# CTRL_MMR0_CFG0 register map
Vendor: Texas Instruments
Registers are 32-bit, read-write, reset 0x0 unless marked. A register's access mark holds for its fields unless they carry their own. Offsets are as the file gives them; [hi:lo] are bit positions; {n}, {i} and the like mark numbered series; 'fields as' and 'values as' point back to an identical list.

## CTRL_MMR0_CFG0 (part 2 of 10)
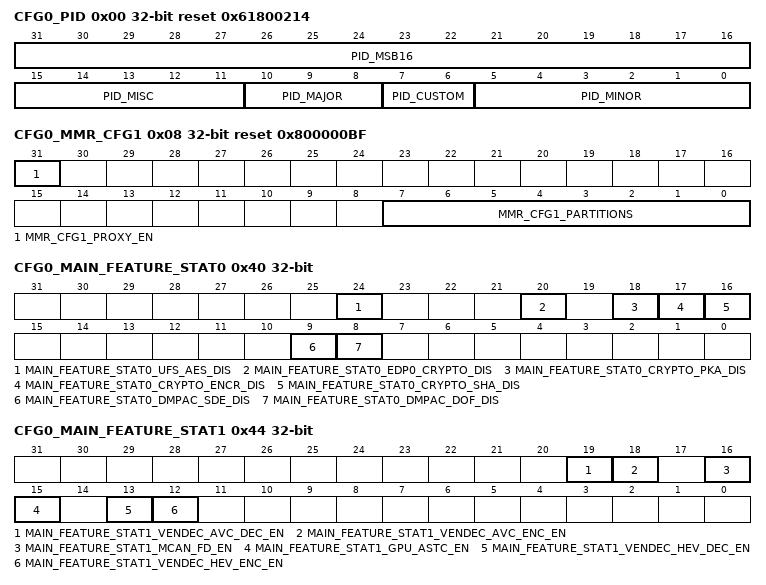
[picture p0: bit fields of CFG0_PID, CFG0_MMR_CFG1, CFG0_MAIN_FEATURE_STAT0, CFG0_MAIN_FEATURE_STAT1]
0x00 CFG0_PID ro reset 0x61800214 — Peripheral release details
  [31:16] PID_MSB16
  [15:11] PID_MISC
  [10:8] PID_MAJOR
  [7:6] PID_CUSTOM — Custom revision number - actual value determined by RTL
  [5:0] PID_MINOR
0x08 CFG0_MMR_CFG1 ro reset 0x800000BF — Indicates the MMR configuration
  [31] MMR_CFG1_PROXY_EN — Proxy addressing enabled
  [7:0] MMR_CFG1_PARTITIONS — Indicates present partitions
0x30 CFG0_MAIN_DEVSTAT — Indicates SoC bootstrap selection. The default value of this register is determined by the SoC bootstrap pins
  [7:0] MAIN_DEVSTAT_BOOTMODE — Specifies the device Primary and Backup boot media.
0x34 CFG0_MAIN_BOOTCFG ro — Indicates SoC bootstrap selection latched at power-on reset. The default value of this register is determined by the SoC bootstrap pins.
  [7:0] MAIN_BOOTCFG_BOOTMODE — Specifies the device Primary and Backup boot media as latched at PORz
0x40 CFG0_MAIN_FEATURE_STAT0 ro — Indicates enable status of MAIN domain IP features
  [24] MAIN_FEATURE_STAT0_UFS_AES_DIS — AES disabled on UFS
  [20] MAIN_FEATURE_STAT0_EDP0_CRYPTO_DIS — HDCP Cryptography disabled on eDP0
  [18] MAIN_FEATURE_STAT0_CRYPTO_PKA_DIS — SA2_UL Crypto Module PKA disabled
  [17] MAIN_FEATURE_STAT0_CRYPTO_ENCR_DIS — SA2_UL Crypto Module AES/3DES/DBRG disabled
  [16] MAIN_FEATURE_STAT0_CRYPTO_SHA_DIS — SA2_UL Crypto Module SHA/MD5 disabled
  [9] MAIN_FEATURE_STAT0_DMPAC_SDE_DIS — DMPAC Stereo Disparity Engine disabled
  [8] MAIN_FEATURE_STAT0_DMPAC_DOF_DIS — DMPAC Dense Optical Flow disabled
0x44 CFG0_MAIN_FEATURE_STAT1 ro — Indicates enable status of MAIN domain IP features
  [19] MAIN_FEATURE_STAT1_VENDEC_AVC_DEC_EN — Video Codec AVC/H.264 decode function enable
  [18] MAIN_FEATURE_STAT1_VENDEC_AVC_ENC_EN — Video Codec AVC/H.264 encode function enable
  [16] MAIN_FEATURE_STAT1_MCAN_FD_EN — FD mode is supported on MAIN MCAN interfaces when set
  [15] MAIN_FEATURE_STAT1_GPU_ASTC_EN — GPU Adaptive Scalable Texture Compression is supported when set
  [13] MAIN_FEATURE_STAT1_VENDEC_HEV_DEC_EN — Video Codec HEVC/H.265 decode function enable
  [12] MAIN_FEATURE_STAT1_VENDEC_HEV_ENC_EN — Video Codec HEVC/H.265 encode function enable
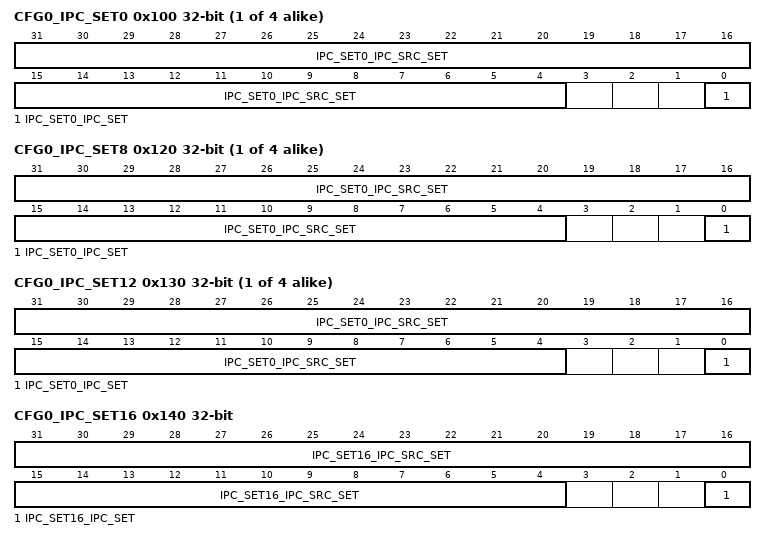
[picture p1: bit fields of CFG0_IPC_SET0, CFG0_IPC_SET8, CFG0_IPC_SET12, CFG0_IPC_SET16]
{0x100+4i} CFG0_IPC_SET{i} access not given (i=0..3) — Generate interprocessor communication interrupt to C71x core{i}
  [31:4] IPC_SET{i}_IPC_SRC_SET — Read returns current valueWrite: 0 - No effect 1 - Sets both SRC_SETx and the SRC_CLRx bit in the corresponding IPC_CLR register (access R/W1TS)
  [0] IPC_SET{i}_IPC_SET — Read returns 0Write: 0 - No effect 1 - Sets both the IPC_SET and the IPC_CLR bit in the corresponding IPC_CLR register (access R/W1TS)
{0x100+4i} CFG0_IPC_SET{i} access not given (i=8..11) — Generate interprocessor communication interrupt to ARM MPU cluster0 core{i-8}
  fields as CFG0_IPC_SET0
{0x100+4i} CFG0_IPC_SET{i} access not given (i=12..15) — Generate interprocessor communication interrupt to ARM MPU cluster1 core{i-12}
  fields as CFG0_IPC_SET0
0x140 CFG0_IPC_SET16 access not given — Generate interprocessor communication interrupt to MAIN R5 cluster0 core0
  [31:4] IPC_SET16_IPC_SRC_SET — Read returns current valueWrite: 0 - No effect 1 - Sets both SRC_SETx and the SRC_CLRx bit in the corresponding IPC_CLR register (access R/W1TS)
  [0] IPC_SET16_IPC_SET — Read returns 0Write: 0 - No effect 1 - Sets both the IPC_SET and the IPC_CLR bit in the corresponding IPC_CLR register (access R/W1TS)
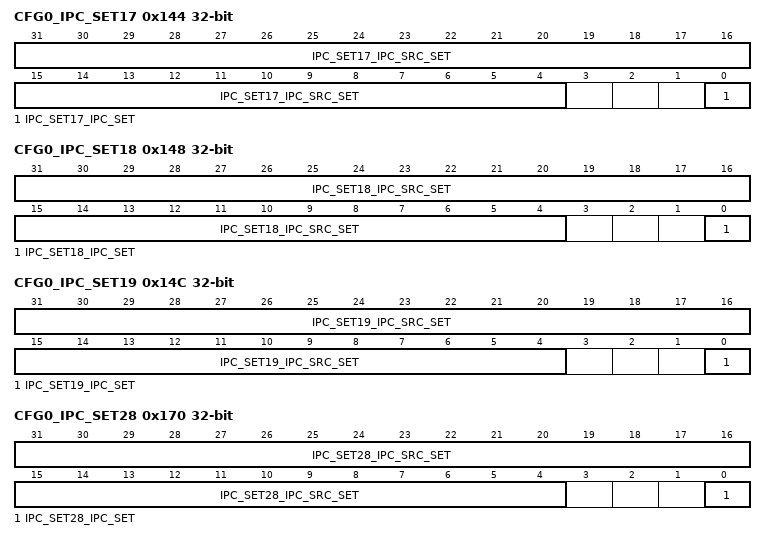
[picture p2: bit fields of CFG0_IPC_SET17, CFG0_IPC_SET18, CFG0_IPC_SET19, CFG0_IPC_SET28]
0x144 CFG0_IPC_SET17 access not given — Generate interprocessor communication interrupt to MAIN R5 cluster0 core1
  [31:4] IPC_SET17_IPC_SRC_SET — Read returns current valueWrite: 0 - No effect 1 - Sets both SRC_SETx and the SRC_CLRx bit in the corresponding IPC_CLR register (access R/W1TS)
  [0] IPC_SET17_IPC_SET — Read returns 0Write: 0 - No effect 1 - Sets both the IPC_SET and the IPC_CLR bit in the corresponding IPC_CLR register (access R/W1TS)
0x148 CFG0_IPC_SET18 access not given — Generate interprocessor communication interrupt to MAIN R5 cluster1 core0
  [31:4] IPC_SET18_IPC_SRC_SET — Read returns current valueWrite: 0 - No effect 1 - Sets both SRC_SETx and the SRC_CLRx bit in the corresponding IPC_CLR register (access R/W1TS)
  [0] IPC_SET18_IPC_SET — Read returns 0Write: 0 - No effect 1 - Sets both the IPC_SET and the IPC_CLR bit in the corresponding IPC_CLR register (access R/W1TS)
0x14C CFG0_IPC_SET19 access not given — Generate interprocessor communication interrupt to MAIN R5 cluster1 core1
  [31:4] IPC_SET19_IPC_SRC_SET — Read returns current valueWrite: 0 - No effect 1 - Sets both SRC_SETx and the SRC_CLRx bit in the corresponding IPC_CLR register (access R/W1TS)
  [0] IPC_SET19_IPC_SET — Read returns 0Write: 0 - No effect 1 - Sets both the IPC_SET and the IPC_CLR bit in the corresponding IPC_CLR register (access R/W1TS)
0x170 CFG0_IPC_SET28 access not given — Generate interprocessor communication interrupt to MAIN R5 cluster2 core0
  [31:4] IPC_SET28_IPC_SRC_SET — Read returns current valueWrite: 0 - No effect 1 - Sets both SRC_SETx and the SRC_CLRx bit in the corresponding IPC_CLR register (access R/W1TS)
  [0] IPC_SET28_IPC_SET — Read returns 0Write: 0 - No effect 1 - Sets both the IPC_SET and the IPC_CLR bit in the corresponding IPC_CLR register (access R/W1TS)
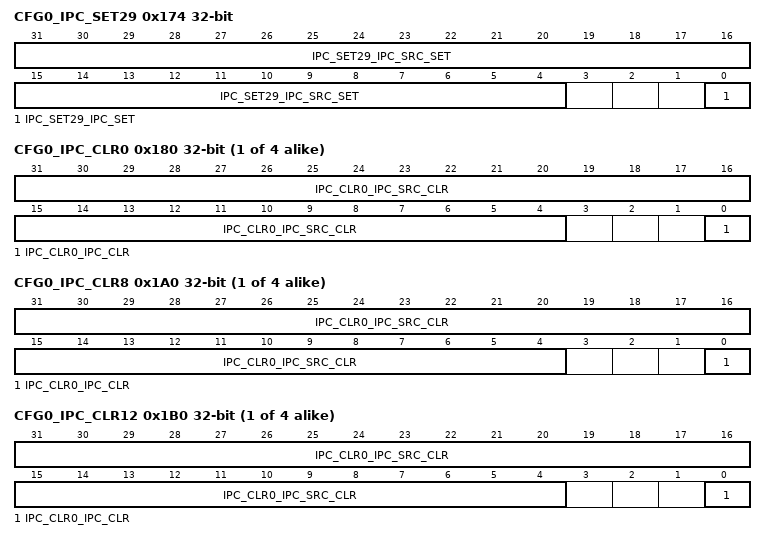
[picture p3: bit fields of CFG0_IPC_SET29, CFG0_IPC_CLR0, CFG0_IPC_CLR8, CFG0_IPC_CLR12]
0x174 CFG0_IPC_SET29 access not given — Generate interprocessor communication interrupt to MAIN R5 cluster2 core1
  [31:4] IPC_SET29_IPC_SRC_SET — Read returns current valueWrite: 0 - No effect 1 - Sets both SRC_SETx and the SRC_CLRx bit in the corresponding IPC_CLR register (access R/W1TS)
  [0] IPC_SET29_IPC_SET — Read returns 0Write: 0 - No effect 1 - Sets both the IPC_SET and the IPC_CLR bit in the corresponding IPC_CLR register (access R/W1TS)
{0x180+4i} CFG0_IPC_CLR{i} access not given (i=0..3) — Acknowledge interprocessor communication interrupt to C71x core{i}
  [31:4] IPC_CLR{i}_IPC_SRC_CLR — Read returns current valueWrite: 0 - No effect 1 - Clears both SRC_CLRx and the SRC_SETx bit in the corresponding IPC_GEN register (access R/W1TC)
  [0] IPC_CLR{i}_IPC_CLR — Read returns current valueWrite: 0 - No effect 1 - Clears both IPC_CLR and the IPC_SET bit in the corresponding IPC_SET register (access R/W1TC)
{0x180+4i} CFG0_IPC_CLR{i} access not given (i=8..11) — Acknowledge interprocessor communication interrupt to ARM MPU cluster0 core{i-8}
  fields as CFG0_IPC_CLR0
{0x180+4i} CFG0_IPC_CLR{i} access not given (i=12..15) — Acknowledge interprocessor communication interrupt to ARM MPU cluster1 core{i-12}
  fields as CFG0_IPC_CLR0
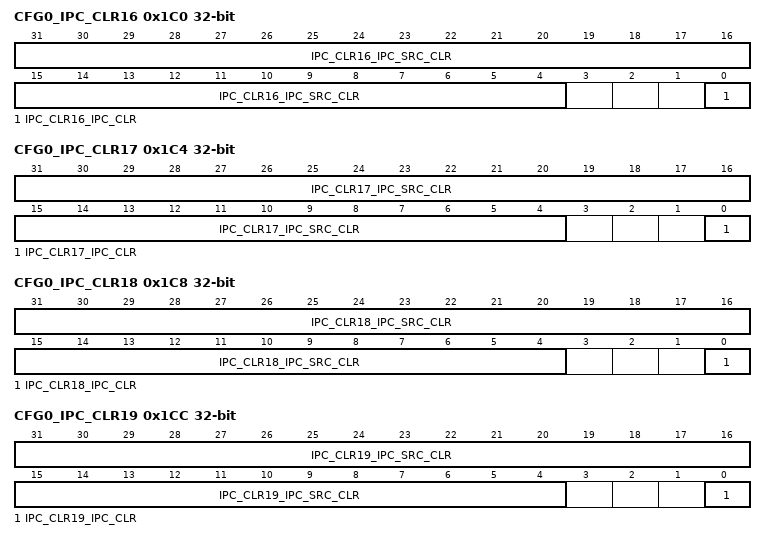
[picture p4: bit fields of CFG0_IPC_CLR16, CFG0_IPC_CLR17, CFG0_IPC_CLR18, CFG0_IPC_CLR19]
0x1C0 CFG0_IPC_CLR16 access not given — Acknowledge interprocessor communication interrupt to MAIN R5 cluster0 core0
  [31:4] IPC_CLR16_IPC_SRC_CLR — Read returns current valueWrite: 0 - No effect 1 - Clears both SRC_CLRx and the SRC_SETx bit in the corresponding IPC_GEN register (access R/W1TC)
  [0] IPC_CLR16_IPC_CLR — Read returns current valueWrite: 0 - No effect 1 - Clears both IPC_CLR and the IPC_SET bit in the corresponding IPC_SET register (access R/W1TC)
0x1C4 CFG0_IPC_CLR17 access not given — Acknowledge interprocessor communication interrupt to MAIN R5 cluster0 core1
  [31:4] IPC_CLR17_IPC_SRC_CLR — Read returns current valueWrite: 0 - No effect 1 - Clears both SRC_CLRx and the SRC_SETx bit in the corresponding IPC_GEN register (access R/W1TC)
  [0] IPC_CLR17_IPC_CLR — Read returns current valueWrite: 0 - No effect 1 - Clears both IPC_CLR and the IPC_SET bit in the corresponding IPC_SET register (access R/W1TC)
0x1C8 CFG0_IPC_CLR18 access not given — Acknowledge interprocessor communication interrupt to MAIN R5 cluster1 core0
  [31:4] IPC_CLR18_IPC_SRC_CLR — Read returns current valueWrite: 0 - No effect 1 - Clears both SRC_CLRx and the SRC_SETx bit in the corresponding IPC_GEN register (access R/W1TC)
  [0] IPC_CLR18_IPC_CLR — Read returns current valueWrite: 0 - No effect 1 - Clears both IPC_CLR and the IPC_SET bit in the corresponding IPC_SET register (access R/W1TC)
0x1CC CFG0_IPC_CLR19 access not given — Acknowledge interprocessor communication interrupt to MAIN R5 cluster1 core1
  [31:4] IPC_CLR19_IPC_SRC_CLR — Read returns current valueWrite: 0 - No effect 1 - Clears both SRC_CLRx and the SRC_SETx bit in the corresponding IPC_GEN register (access R/W1TC)
  [0] IPC_CLR19_IPC_CLR — Read returns current valueWrite: 0 - No effect 1 - Clears both IPC_CLR and the IPC_SET bit in the corresponding IPC_SET register (access R/W1TC)
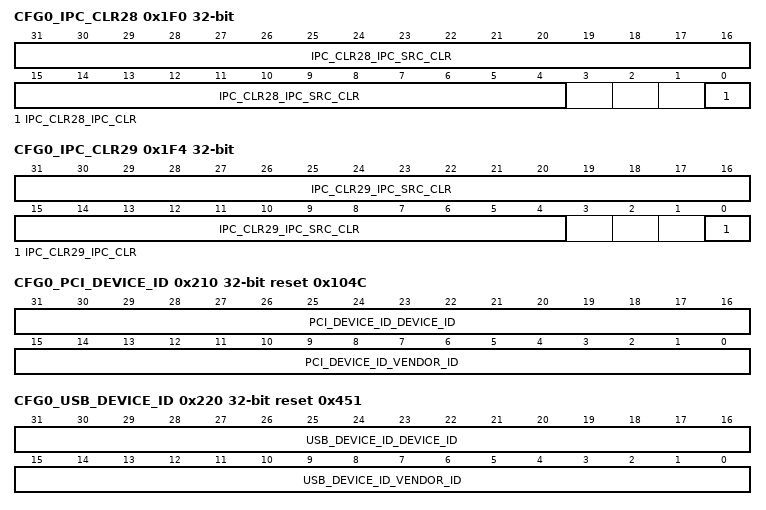
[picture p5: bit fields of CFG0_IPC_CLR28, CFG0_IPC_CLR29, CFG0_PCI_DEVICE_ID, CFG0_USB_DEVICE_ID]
0x1F0 CFG0_IPC_CLR28 access not given — Acknowledge interprocessor communication interrupt to MAIN R5 cluster2 core0
  [31:4] IPC_CLR28_IPC_SRC_CLR — Read returns current valueWrite: 0 - No effect 1 - Clears both SRC_CLRx and the SRC_SETx bit in the corresponding IPC_GEN register (access R/W1TC)
  [0] IPC_CLR28_IPC_CLR — Read returns current valueWrite: 0 - No effect 1 - Clears both IPC_CLR and the IPC_SET bit in the corresponding IPC_SET register (access R/W1TC)
0x1F4 CFG0_IPC_CLR29 access not given — Acknowledge interprocessor communication interrupt to MAIN R5 cluster2 core1
  [31:4] IPC_CLR29_IPC_SRC_CLR — Read returns current valueWrite: 0 - No effect 1 - Clears both SRC_CLRx and the SRC_SETx bit in the corresponding IPC_GEN register (access R/W1TC)
  [0] IPC_CLR29_IPC_CLR — Read returns current valueWrite: 0 - No effect 1 - Clears both IPC_CLR and the IPC_SET bit in the corresponding IPC_SET register (access R/W1TC)
0x210 CFG0_PCI_DEVICE_ID reset 0x104C — PCIe device ID and vendor ID register
  [31:16] PCI_DEVICE_ID_DEVICE_ID — Product ID defaults to 16'hB012
  [15:0] PCI_DEVICE_ID_VENDOR_ID — TI Vendor ID
0x220 CFG0_USB_DEVICE_ID reset 0x451 — USB device and vendor ID register
  [31:16] USB_DEVICE_ID_DEVICE_ID — Product ID defaults to 16'h6167
  [15:0] USB_DEVICE_ID_VENDOR_ID — TI Vendor ID
{0x1008+0x4000*i} CFG0_LOCK{i}_KICK0 (i=0..3) — This register must be written with the designated key value followed by a write to LOCK{i}_KICK1 with its key value before write-protected Partition {i} registers can be written.
  [31:0] LOCK{i}_KICK0 — - KICK0 component
{0x100C+0x4000*i} CFG0_LOCK{i}_KICK1 (i=0..3) — This register must be written with the designated key value after a write to LOCK{i}_KICK0 with its key value before write-protected Partition {i} registers can be written.
  [31:0] LOCK{i}_KICK1 — - KICK1 component
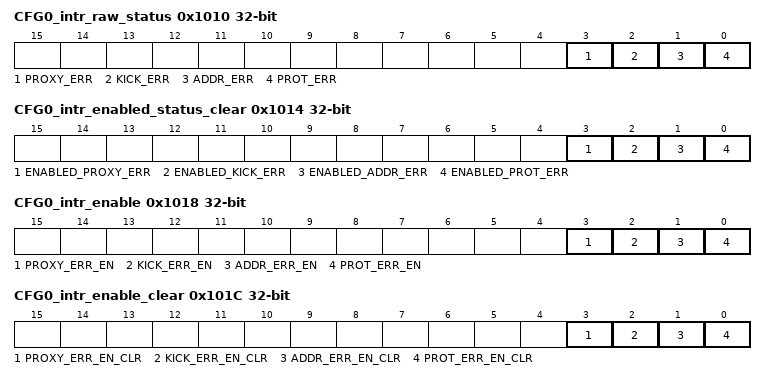
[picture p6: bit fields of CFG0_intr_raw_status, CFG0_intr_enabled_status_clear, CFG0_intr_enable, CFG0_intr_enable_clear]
0x1010 CFG0_intr_raw_status access not given
  [3] PROXY_ERR — Proxy0 access violation error. Raw status is read. Write a 1 to set the status. Writing a 0 has no effect. (access R/W1TS)
  [2] KICK_ERR — Kick access violation error. Raw status is read. Write a 1 to set the status. Writing a 0 has no effect. (access R/W1TS)
  [1] ADDR_ERR — Addressing violation error. Raw status is read. Write a 1 to set the status. Writing a 0 has no effect. (access R/W1TS)
  [0] PROT_ERR — Protection violation error. Raw status is read. Write a 1 to set the status. Writing a 0 has no effect. (access R/W1TS)
0x1014 CFG0_intr_enabled_status_clear access not given
  [3] ENABLED_PROXY_ERR — Proxy0 access violation error. Enabled status is read. Write a 1 to clear the status. Writing a 0 has no effect. (access R/W1TC)
  [2] ENABLED_KICK_ERR — Kick access violation error. Enabled status is read. Write a 1 to clear the status. Writing a 0 has no effect. (access R/W1TC)
  [1] ENABLED_ADDR_ERR — Addressing violation error. Enabled status is read. Write a 1 to clear the status. Writing a 0 has no effect. (access R/W1TC)
  [0] ENABLED_PROT_ERR — Protection violation error. Enabled status is read. Write a 1 to clear the status. Writing a 0 has no effect. (access R/W1TC)
0x1018 CFG0_intr_enable access not given
  [3] PROXY_ERR_EN — Proxy0 access violation error enable. Write a 1 to set the enable. Writing a 0 has no effect. (access R/W1TS)
  [2] KICK_ERR_EN — Kick access violation error enable. Write a 1 to set the enable. Writing a 0 has no effect. (access R/W1TS)
  [1] ADDR_ERR_EN — Addressing violation error enable. Write a 1 to set the enable. Writing a 0 has no effect. (access R/W1TS)
  [0] PROT_ERR_EN — Protection violation error enable. Write a 1 to set the enable. Writing a 0 has no effect. (access R/W1TS)
0x101C CFG0_intr_enable_clear access not given
  [3] PROXY_ERR_EN_CLR — Proxy0 access violation error enable clear. Write a 1 to clear the enable. Writing a 0 has no effect. (access R/W1TC)
  [2] KICK_ERR_EN_CLR — Kick access violation error enable clear. Write a 1 to clear the enable. Writing a 0 has no effect. (access R/W1TC)
  [1] ADDR_ERR_EN_CLR — Addressing violation error enable clear. Write a 1 to clear the enable. Writing a 0 has no effect. (access R/W1TC)
  [0] PROT_ERR_EN_CLR — Protection violation error enable clear. Write a 1 to clear the enable. Writing a 0 has no effect. (access R/W1TC)
0x1020 CFG0_eoi — This register should be written with interrupt distribution value required by the device architecture to indicate service completion of the MMR interrupt. This value is not used on this device.
  [7:0] EOI_VECTOR — EOI vector value. Write this with interrupt distribution value in the chip.
0x1024 CFG0_fault_address ro
  [31:0] FAULT_ADDR — Fault Address.
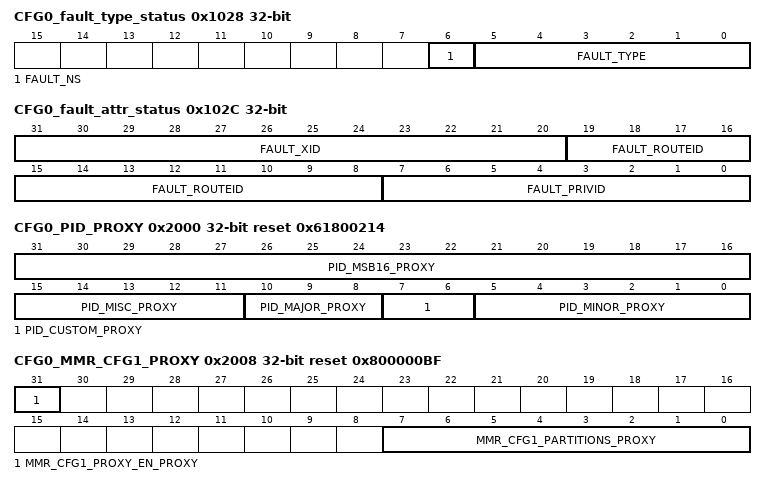
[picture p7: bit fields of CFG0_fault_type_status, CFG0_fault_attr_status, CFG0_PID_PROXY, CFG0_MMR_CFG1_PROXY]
0x1028 CFG0_fault_type_status ro
  [6] FAULT_NS — Non-secure access.
  [5:0] FAULT_TYPE — Fault Type 10_0000 = Supervisor read fault - priv = 1 dir = 1 dtype != 1 01_0000 = Supervisor write fault - priv = 1 dir = 0 00_1000 = Supervisor execute fault - priv = 1 dir = 1 dtype = 1 00_0100 = User read fault - priv = 0 dir = 1 dtype = 1 00_0010 = User write fault - priv = 0 dir = 0 00_0001 = User execute fault - priv = 0 dir = 1 dtype = 1 00_0000 = No fault
0x102C CFG0_fault_attr_status ro
  [31:20] FAULT_XID — XID.
  [19:8] FAULT_ROUTEID — Route ID.
  [7:0] FAULT_PRIVID — Privilege ID.
0x1030 CFG0_fault_clear wo
  [0] FAULT_CLR — Fault clear. Writing a 1 clears the current fault. Writing a 0 has no effect.
{0x1100+4i} CFG0_CLAIMREG_P0_R{i}_READONLY ro (i=0..6)
  [31:0] CLAIMREG_P0_R{i}_READONLY — Claim bits for Partition 0
0x2000 CFG0_PID_PROXY ro reset 0x61800214 — Peripheral release details
  [31:16] PID_MSB16_PROXY
  [15:11] PID_MISC_PROXY
  [10:8] PID_MAJOR_PROXY
  [7:6] PID_CUSTOM_PROXY — Custom revision number - actual value determined by RTL
  [5:0] PID_MINOR_PROXY
0x2008 CFG0_MMR_CFG1_PROXY ro reset 0x800000BF — Indicates the MMR configuration
  [31] MMR_CFG1_PROXY_EN_PROXY — Proxy addressing enabled
  [7:0] MMR_CFG1_PARTITIONS_PROXY — Indicates present partitions
0x2030 CFG0_MAIN_DEVSTAT_PROXY — Indicates SoC bootstrap selection. The default value of this register is determined by the SoC bootstrap pins
  [7:0] MAIN_DEVSTAT_BOOTMODE_PROXY — Specifies the device Primary and Backup boot media.
0x2034 CFG0_MAIN_BOOTCFG_PROXY ro — Indicates SoC bootstrap selection latched at power-on reset. The default value of this register is determined by the SoC bootstrap pins.
  [7:0] MAIN_BOOTCFG_BOOTMODE_PROXY — Specifies the device Primary and Backup boot media as latched at PORz
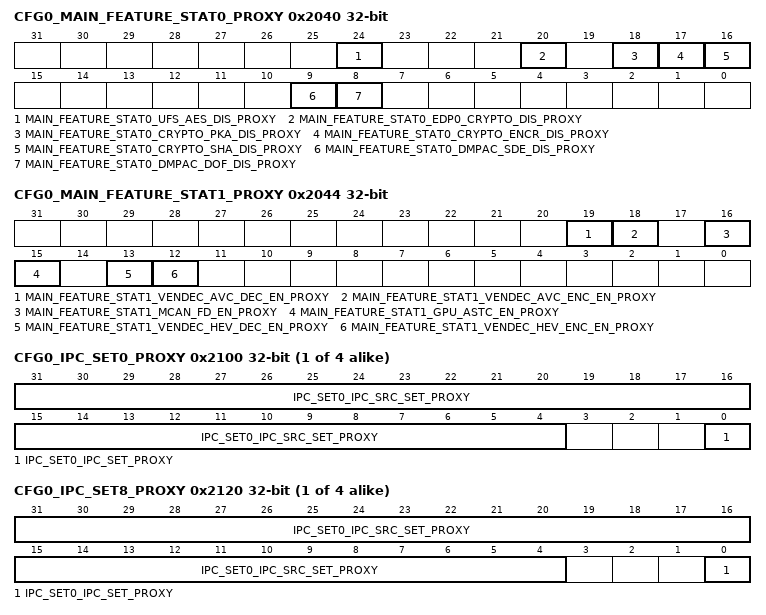
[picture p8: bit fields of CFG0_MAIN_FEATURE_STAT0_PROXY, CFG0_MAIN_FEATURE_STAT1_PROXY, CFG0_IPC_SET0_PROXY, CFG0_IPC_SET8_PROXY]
0x2040 CFG0_MAIN_FEATURE_STAT0_PROXY ro — Indicates enable status of MAIN domain IP features
  [24] MAIN_FEATURE_STAT0_UFS_AES_DIS_PROXY — AES disabled on UFS
  [20] MAIN_FEATURE_STAT0_EDP0_CRYPTO_DIS_PROXY — HDCP Cryptography disabled on eDP0
  [18] MAIN_FEATURE_STAT0_CRYPTO_PKA_DIS_PROXY — SA2_UL Crypto Module PKA disabled
  [17] MAIN_FEATURE_STAT0_CRYPTO_ENCR_DIS_PROXY — SA2_UL Crypto Module AES/3DES/DBRG disabled
  [16] MAIN_FEATURE_STAT0_CRYPTO_SHA_DIS_PROXY — SA2_UL Crypto Module SHA/MD5 disabled
  [9] MAIN_FEATURE_STAT0_DMPAC_SDE_DIS_PROXY — DMPAC Stereo Disparity Engine disabled
  [8] MAIN_FEATURE_STAT0_DMPAC_DOF_DIS_PROXY — DMPAC Dense Optical Flow disabled
0x2044 CFG0_MAIN_FEATURE_STAT1_PROXY ro — Indicates enable status of MAIN domain IP features
  [19] MAIN_FEATURE_STAT1_VENDEC_AVC_DEC_EN_PROXY — Video Codec AVC/H.264 decode function enable
  [18] MAIN_FEATURE_STAT1_VENDEC_AVC_ENC_EN_PROXY — Video Codec AVC/H.264 encode function enable
  [16] MAIN_FEATURE_STAT1_MCAN_FD_EN_PROXY — FD mode is supported on MAIN MCAN interfaces when set
  [15] MAIN_FEATURE_STAT1_GPU_ASTC_EN_PROXY — GPU Adaptive Scalable Texture Compression is supported when set
  [13] MAIN_FEATURE_STAT1_VENDEC_HEV_DEC_EN_PROXY — Video Codec HEVC/H.265 decode function enable
  [12] MAIN_FEATURE_STAT1_VENDEC_HEV_ENC_EN_PROXY — Video Codec HEVC/H.265 encode function enable
{0x2100+4i} CFG0_IPC_SET{i}_PROXY access not given (i=0..3) — Generate interprocessor communication interrupt to C71x core{i}
  [31:4] IPC_SET{i}_IPC_SRC_SET_PROXY — Read returns current valueWrite: 0 - No effect 1 - Sets both SRC_SETx and the SRC_CLRx bit in the corresponding IPC_CLR register (access R/W1TS)
  [0] IPC_SET{i}_IPC_SET_PROXY — Read returns 0Write: 0 - No effect 1 - Sets both the IPC_SET and the IPC_CLR bit in the corresponding IPC_CLR register (access R/W1TS)
{0x2100+4i} CFG0_IPC_SET{i}_PROXY access not given (i=8..11) — Generate interprocessor communication interrupt to ARM MPU cluster0 core{i-8}
  fields as CFG0_IPC_SET0_PROXY
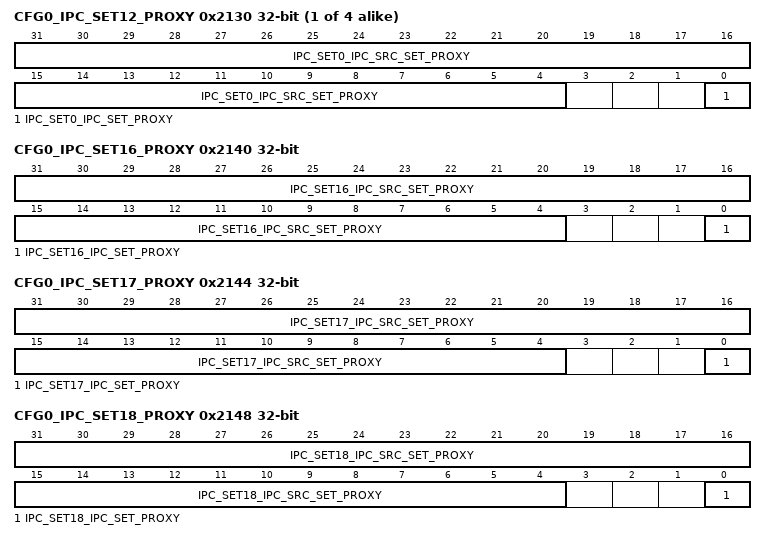
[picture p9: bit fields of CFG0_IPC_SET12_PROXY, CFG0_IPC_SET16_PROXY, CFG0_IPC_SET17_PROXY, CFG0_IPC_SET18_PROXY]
{0x2100+4i} CFG0_IPC_SET{i}_PROXY access not given (i=12..15) — Generate interprocessor communication interrupt to ARM MPU cluster1 core{i-12}
  fields as CFG0_IPC_SET0_PROXY
0x2140 CFG0_IPC_SET16_PROXY access not given — Generate interprocessor communication interrupt to MAIN R5 cluster0 core0
  [31:4] IPC_SET16_IPC_SRC_SET_PROXY — Read returns current valueWrite: 0 - No effect 1 - Sets both SRC_SETx and the SRC_CLRx bit in the corresponding IPC_CLR register (access R/W1TS)
  [0] IPC_SET16_IPC_SET_PROXY — Read returns 0Write: 0 - No effect 1 - Sets both the IPC_SET and the IPC_CLR bit in the corresponding IPC_CLR register (access R/W1TS)
0x2144 CFG0_IPC_SET17_PROXY access not given — Generate interprocessor communication interrupt to MAIN R5 cluster0 core1
  [31:4] IPC_SET17_IPC_SRC_SET_PROXY — Read returns current valueWrite: 0 - No effect 1 - Sets both SRC_SETx and the SRC_CLRx bit in the corresponding IPC_CLR register (access R/W1TS)
  [0] IPC_SET17_IPC_SET_PROXY — Read returns 0Write: 0 - No effect 1 - Sets both the IPC_SET and the IPC_CLR bit in the corresponding IPC_CLR register (access R/W1TS)
0x2148 CFG0_IPC_SET18_PROXY access not given — Generate interprocessor communication interrupt to MAIN R5 cluster1 core0
  [31:4] IPC_SET18_IPC_SRC_SET_PROXY — Read returns current valueWrite: 0 - No effect 1 - Sets both SRC_SETx and the SRC_CLRx bit in the corresponding IPC_CLR register (access R/W1TS)
  [0] IPC_SET18_IPC_SET_PROXY — Read returns 0Write: 0 - No effect 1 - Sets both the IPC_SET and the IPC_CLR bit in the corresponding IPC_CLR register (access R/W1TS)
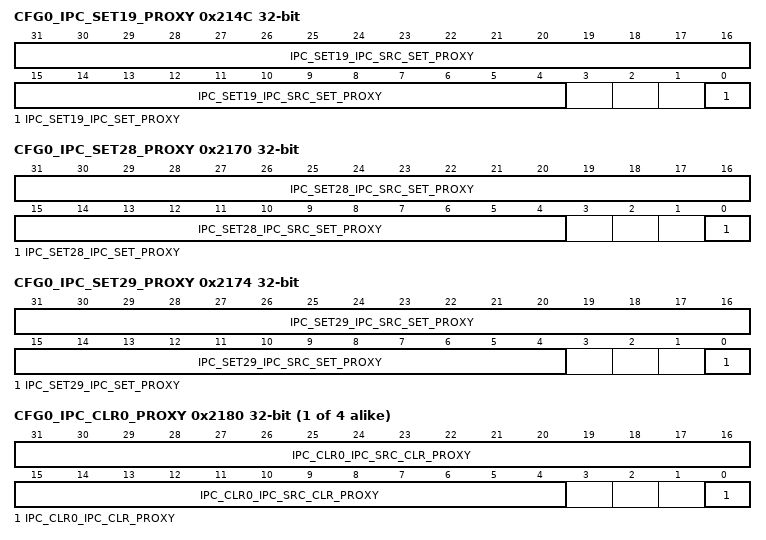
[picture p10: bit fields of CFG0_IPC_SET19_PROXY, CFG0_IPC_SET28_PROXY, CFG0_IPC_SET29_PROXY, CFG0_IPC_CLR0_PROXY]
0x214C CFG0_IPC_SET19_PROXY access not given — Generate interprocessor communication interrupt to MAIN R5 cluster1 core1
  [31:4] IPC_SET19_IPC_SRC_SET_PROXY — Read returns current valueWrite: 0 - No effect 1 - Sets both SRC_SETx and the SRC_CLRx bit in the corresponding IPC_CLR register (access R/W1TS)
  [0] IPC_SET19_IPC_SET_PROXY — Read returns 0Write: 0 - No effect 1 - Sets both the IPC_SET and the IPC_CLR bit in the corresponding IPC_CLR register (access R/W1TS)
0x2170 CFG0_IPC_SET28_PROXY access not given — Generate interprocessor communication interrupt to MAIN R5 cluster2 core0
  [31:4] IPC_SET28_IPC_SRC_SET_PROXY — Read returns current valueWrite: 0 - No effect 1 - Sets both SRC_SETx and the SRC_CLRx bit in the corresponding IPC_CLR register (access R/W1TS)
  [0] IPC_SET28_IPC_SET_PROXY — Read returns 0Write: 0 - No effect 1 - Sets both the IPC_SET and the IPC_CLR bit in the corresponding IPC_CLR register (access R/W1TS)
0x2174 CFG0_IPC_SET29_PROXY access not given — Generate interprocessor communication interrupt to MAIN R5 cluster2 core1
  [31:4] IPC_SET29_IPC_SRC_SET_PROXY — Read returns current valueWrite: 0 - No effect 1 - Sets both SRC_SETx and the SRC_CLRx bit in the corresponding IPC_CLR register (access R/W1TS)
  [0] IPC_SET29_IPC_SET_PROXY — Read returns 0Write: 0 - No effect 1 - Sets both the IPC_SET and the IPC_CLR bit in the corresponding IPC_CLR register (access R/W1TS)
{0x2180+4i} CFG0_IPC_CLR{i}_PROXY access not given (i=0..3) — Acknowledge interprocessor communication interrupt to C71x core{i}
  [31:4] IPC_CLR{i}_IPC_SRC_CLR_PROXY — Read returns current valueWrite: 0 - No effect 1 - Clears both SRC_CLRx and the SRC_SETx bit in the corresponding IPC_GEN register (access R/W1TC)
  [0] IPC_CLR{i}_IPC_CLR_PROXY — Read returns current valueWrite: 0 - No effect 1 - Clears both IPC_CLR and the IPC_SET bit in the corresponding IPC_SET register (access R/W1TC)
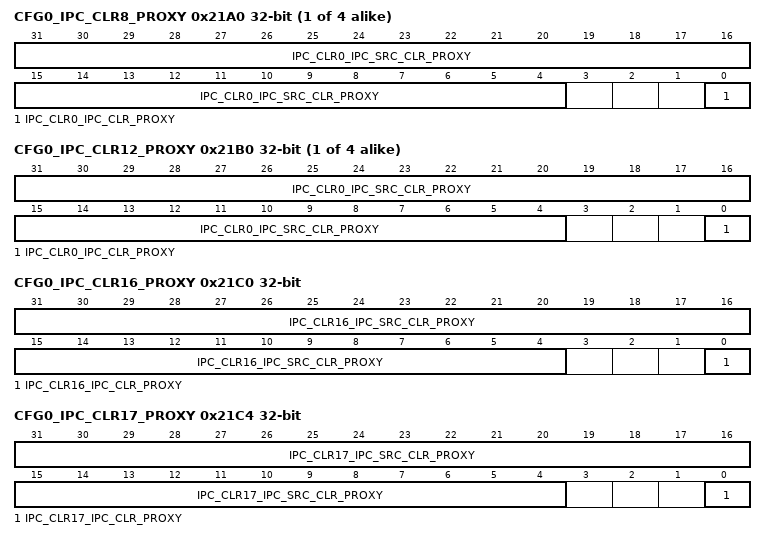
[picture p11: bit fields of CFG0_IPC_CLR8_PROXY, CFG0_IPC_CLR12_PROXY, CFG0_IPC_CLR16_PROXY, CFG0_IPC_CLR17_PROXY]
{0x2180+4i} CFG0_IPC_CLR{i}_PROXY access not given (i=8..11) — Acknowledge interprocessor communication interrupt to ARM MPU cluster0 core{i-8}
  fields as CFG0_IPC_CLR0_PROXY
{0x2180+4i} CFG0_IPC_CLR{i}_PROXY access not given (i=12..15) — Acknowledge interprocessor communication interrupt to ARM MPU cluster1 core{i-12}
  fields as CFG0_IPC_CLR0_PROXY
0x21C0 CFG0_IPC_CLR16_PROXY access not given — Acknowledge interprocessor communication interrupt to MAIN R5 cluster0 core0
  [31:4] IPC_CLR16_IPC_SRC_CLR_PROXY — Read returns current valueWrite: 0 - No effect 1 - Clears both SRC_CLRx and the SRC_SETx bit in the corresponding IPC_GEN register (access R/W1TC)
  [0] IPC_CLR16_IPC_CLR_PROXY — Read returns current valueWrite: 0 - No effect 1 - Clears both IPC_CLR and the IPC_SET bit in the corresponding IPC_SET register (access R/W1TC)
0x21C4 CFG0_IPC_CLR17_PROXY access not given — Acknowledge interprocessor communication interrupt to MAIN R5 cluster0 core1
  [31:4] IPC_CLR17_IPC_SRC_CLR_PROXY — Read returns current valueWrite: 0 - No effect 1 - Clears both SRC_CLRx and the SRC_SETx bit in the corresponding IPC_GEN register (access R/W1TC)
  [0] IPC_CLR17_IPC_CLR_PROXY — Read returns current valueWrite: 0 - No effect 1 - Clears both IPC_CLR and the IPC_SET bit in the corresponding IPC_SET register (access R/W1TC)
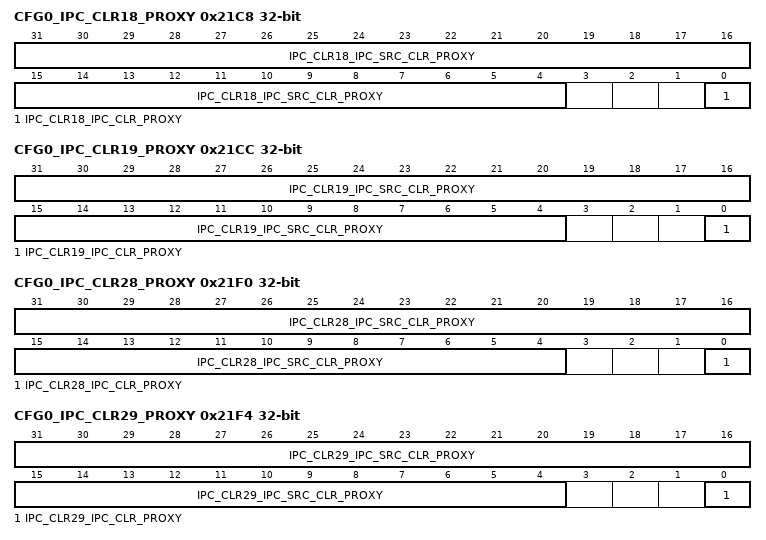
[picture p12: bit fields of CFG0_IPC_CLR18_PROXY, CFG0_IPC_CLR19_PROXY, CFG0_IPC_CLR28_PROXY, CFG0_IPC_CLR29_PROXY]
0x21C8 CFG0_IPC_CLR18_PROXY access not given — Acknowledge interprocessor communication interrupt to MAIN R5 cluster1 core0
  [31:4] IPC_CLR18_IPC_SRC_CLR_PROXY — Read returns current valueWrite: 0 - No effect 1 - Clears both SRC_CLRx and the SRC_SETx bit in the corresponding IPC_GEN register (access R/W1TC)
  [0] IPC_CLR18_IPC_CLR_PROXY — Read returns current valueWrite: 0 - No effect 1 - Clears both IPC_CLR and the IPC_SET bit in the corresponding IPC_SET register (access R/W1TC)
0x21CC CFG0_IPC_CLR19_PROXY access not given — Acknowledge interprocessor communication interrupt to MAIN R5 cluster1 core1
  [31:4] IPC_CLR19_IPC_SRC_CLR_PROXY — Read returns current valueWrite: 0 - No effect 1 - Clears both SRC_CLRx and the SRC_SETx bit in the corresponding IPC_GEN register (access R/W1TC)
  [0] IPC_CLR19_IPC_CLR_PROXY — Read returns current valueWrite: 0 - No effect 1 - Clears both IPC_CLR and the IPC_SET bit in the corresponding IPC_SET register (access R/W1TC)
0x21F0 CFG0_IPC_CLR28_PROXY access not given — Acknowledge interprocessor communication interrupt to MAIN R5 cluster2 core0
  [31:4] IPC_CLR28_IPC_SRC_CLR_PROXY — Read returns current valueWrite: 0 - No effect 1 - Clears both SRC_CLRx and the SRC_SETx bit in the corresponding IPC_GEN register (access R/W1TC)
  [0] IPC_CLR28_IPC_CLR_PROXY — Read returns current valueWrite: 0 - No effect 1 - Clears both IPC_CLR and the IPC_SET bit in the corresponding IPC_SET register (access R/W1TC)
0x21F4 CFG0_IPC_CLR29_PROXY access not given — Acknowledge interprocessor communication interrupt to MAIN R5 cluster2 core1
  [31:4] IPC_CLR29_IPC_SRC_CLR_PROXY — Read returns current valueWrite: 0 - No effect 1 - Clears both SRC_CLRx and the SRC_SETx bit in the corresponding IPC_GEN register (access R/W1TC)
  [0] IPC_CLR29_IPC_CLR_PROXY — Read returns current valueWrite: 0 - No effect 1 - Clears both IPC_CLR and the IPC_SET bit in the corresponding IPC_SET register (access R/W1TC)
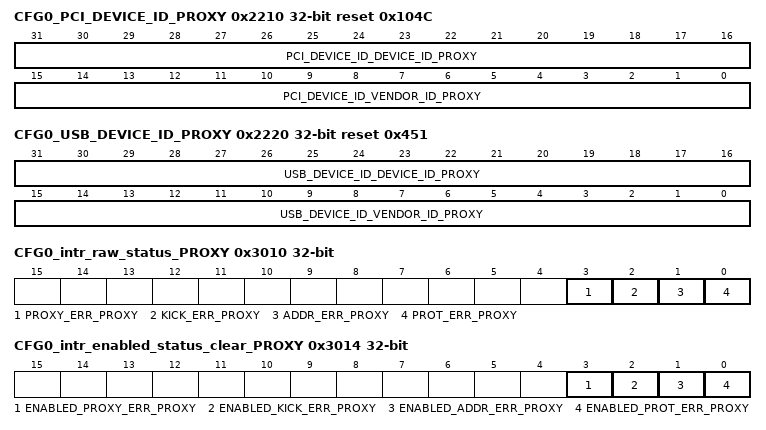
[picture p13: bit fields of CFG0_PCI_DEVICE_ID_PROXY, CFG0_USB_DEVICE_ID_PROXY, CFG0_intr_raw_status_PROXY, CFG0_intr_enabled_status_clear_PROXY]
0x2210 CFG0_PCI_DEVICE_ID_PROXY reset 0x104C — PCIe device ID and vendor ID register
  [31:16] PCI_DEVICE_ID_DEVICE_ID_PROXY — Product ID defaults to 16'hB012
  [15:0] PCI_DEVICE_ID_VENDOR_ID_PROXY — TI Vendor ID
0x2220 CFG0_USB_DEVICE_ID_PROXY reset 0x451 — USB device and vendor ID register
  [31:16] USB_DEVICE_ID_DEVICE_ID_PROXY — Product ID defaults to 16'h6167
  [15:0] USB_DEVICE_ID_VENDOR_ID_PROXY — TI Vendor ID
{0x3008+0x4000*i} CFG0_LOCK{i}_KICK0_PROXY (i=0..3) — This register must be written with the designated key value followed by a write to LOCK{i}_KICK1 with its key value before write-protected Partition {i} registers can be written.
  [31:0] LOCK{i}_KICK0_PROXY — - KICK0 component
{0x300C+0x4000*i} CFG0_LOCK{i}_KICK1_PROXY (i=0..3) — This register must be written with the designated key value after a write to LOCK{i}_KICK0 with its key value before write-protected Partition {i} registers can be written.
  [31:0] LOCK{i}_KICK1_PROXY — - KICK1 component
0x3010 CFG0_intr_raw_status_PROXY access not given
  [3] PROXY_ERR_PROXY — Proxy0 access violation error. Raw status is read. Write a 1 to set the status. Writing a 0 has no effect. (access R/W1TS)
  [2] KICK_ERR_PROXY — Kick access violation error. Raw status is read. Write a 1 to set the status. Writing a 0 has no effect. (access R/W1TS)
  [1] ADDR_ERR_PROXY — Addressing violation error. Raw status is read. Write a 1 to set the status. Writing a 0 has no effect. (access R/W1TS)
  [0] PROT_ERR_PROXY — Protection violation error. Raw status is read. Write a 1 to set the status. Writing a 0 has no effect. (access R/W1TS)
0x3014 CFG0_intr_enabled_status_clear_PROXY access not given
  [3] ENABLED_PROXY_ERR_PROXY — Proxy0 access violation error. Enabled status is read. Write a 1 to clear the status. Writing a 0 has no effect. (access R/W1TC)
  [2] ENABLED_KICK_ERR_PROXY — Kick access violation error. Enabled status is read. Write a 1 to clear the status. Writing a 0 has no effect. (access R/W1TC)
  [1] ENABLED_ADDR_ERR_PROXY — Addressing violation error. Enabled status is read. Write a 1 to clear the status. Writing a 0 has no effect. (access R/W1TC)
  [0] ENABLED_PROT_ERR_PROXY — Protection violation error. Enabled status is read. Write a 1 to clear the status. Writing a 0 has no effect. (access R/W1TC)
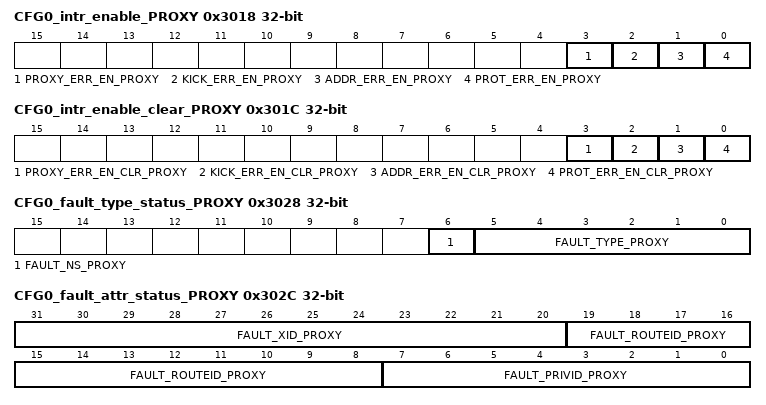
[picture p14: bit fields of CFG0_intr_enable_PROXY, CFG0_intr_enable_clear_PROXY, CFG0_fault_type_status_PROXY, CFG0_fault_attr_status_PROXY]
0x3018 CFG0_intr_enable_PROXY access not given
  [3] PROXY_ERR_EN_PROXY — Proxy0 access violation error enable. Write a 1 to set the enable. Writing a 0 has no effect. (access R/W1TS)
  [2] KICK_ERR_EN_PROXY — Kick access violation error enable. Write a 1 to set the enable. Writing a 0 has no effect. (access R/W1TS)
  [1] ADDR_ERR_EN_PROXY — Addressing violation error enable. Write a 1 to set the enable. Writing a 0 has no effect. (access R/W1TS)
  [0] PROT_ERR_EN_PROXY — Protection violation error enable. Write a 1 to set the enable. Writing a 0 has no effect. (access R/W1TS)
0x301C CFG0_intr_enable_clear_PROXY access not given
  [3] PROXY_ERR_EN_CLR_PROXY — Proxy0 access violation error enable clear. Write a 1 to clear the enable. Writing a 0 has no effect. (access R/W1TC)
  [2] KICK_ERR_EN_CLR_PROXY — Kick access violation error enable clear. Write a 1 to clear the enable. Writing a 0 has no effect. (access R/W1TC)
  [1] ADDR_ERR_EN_CLR_PROXY — Addressing violation error enable clear. Write a 1 to clear the enable. Writing a 0 has no effect. (access R/W1TC)
  [0] PROT_ERR_EN_CLR_PROXY — Protection violation error enable clear. Write a 1 to clear the enable. Writing a 0 has no effect. (access R/W1TC)
0x3020 CFG0_eoi_PROXY — This register should be written with interrupt distribution value required by the device architecture to indicate service completion of the MMR interrupt. This value is not used on this device.
  [7:0] EOI_VECTOR_PROXY — EOI vector value. Write this with interrupt distribution value in the chip.
0x3024 CFG0_fault_address_PROXY ro
  [31:0] FAULT_ADDR_PROXY — Fault Address.
0x3028 CFG0_fault_type_status_PROXY ro
  [6] FAULT_NS_PROXY — Non-secure access.
  [5:0] FAULT_TYPE_PROXY — Fault Type 10_0000 = Supervisor read fault - priv = 1 dir = 1 dtype != 1 01_0000 = Supervisor write fault - priv = 1 dir = 0 00_1000 = Supervisor execute fault - priv = 1 dir = 1 dtype = 1 00_0100 = User read fault - priv = 0 dir = 1 dtype = 1 00_0010 = User write fault - priv = 0 dir = 0 00_0001 = User execute fault - priv = 0 dir = 1 dtype = 1 00_0000 = No fault
0x302C CFG0_fault_attr_status_PROXY ro
  [31:20] FAULT_XID_PROXY — XID.
  [19:8] FAULT_ROUTEID_PROXY — Route ID.
  [7:0] FAULT_PRIVID_PROXY — Privilege ID.
0x3030 CFG0_fault_clear_PROXY wo
  [0] FAULT_CLR_PROXY — Fault clear. Writing a 1 clears the current fault. Writing a 0 has no effect.
{0x3100+4i} CFG0_CLAIMREG_P0_R{i} (i=0..6)
  [31:0] CLAIMREG_P0_R{i} — Claim bits for Partition 0
0x4000 CFG0_USB0_CTRL — Controls USB0 operation
  [27] USB0_CTRL_SERDES_SEL — Serdes Selection.The USB3_0 interface can be mapped to 2 different SERDES lanes. This bit selects which SERDES drives the USB3 PIPE interface input clock, data and control signals. Programming should align with the SERDES0_LN3_CTRL and SERDES2_LN3_CTRL lane_func_sel programming. 0 - SERDES0 Ln3 drives USB3_0 inputs 1 - SERDES4 Ln3 drives USB3_0 inputs
0x4008 CFG0_USB0_PHY_CTRL reset 0x80000000 — Configures the USB0 Phy operation
  [31] USB0_PHY_CTRL_CORE_VOLTAGE — Selects the USB PHY core voltage 0 - Core voltage is 0.85 V 1 - Core voltage is 0.80 V
0x4034 CFG0_CPSW2_ENET1_CTRL reset 0x2 — Controls MAIN CPSW_2G Ethernet Port1 operation
  [4] CPSW2_ENET1_CTRL_RGMII_ID_MODE — Port 1 RGMII internal transmit delay selection 0 - Internal transmit delay 1 - No internal transmit delay
  [1:0] CPSW2_ENET1_CTRL_MODE_SEL — Selects Ethernet switch Port1 interface Field values (Others are reserved): 2'b00 - GMII/MII (not supported) 2'b01 - RMII 2'b10 - RGMII 2'b11 - SGMII (not supported)
{0x4040+4i} CFG0_ENET{i}_CTRL reset 0x2 (i=1..8) — Controls Ethernet Port{i} operation
  [4] ENET{i}_CTRL_RGMII_ID_MODE — Port{i} RGMII internal transmit delay selection 0 - Internal transmit delay 1 - No internal transmit delay
  [2:0] ENET{i}_CTRL_PORT_MODE_SEL — Selects Ethernet switch Port{i} interface Field values (Others are reserved): 3'b000 - GMII/MII (not supported) 3'b001 - RMII (not supported) 3'b010 - RGMII (not supported) 3'b011 - SGMII 3'b100 - QSGMII 3'b101 - USXGMII/XFI 3'b110 - QSGMII_SUB 3'b111 - Reserved
0x4070 CFG0_PCIE0_CTRL reset 0x2 — Controls PCIe0 operation
  [9:8] PCIE0_CTRL_LANE_COUNT — Configures the PCIe lane count 00 - Select 1-lane operation 01 - Select 2-lane operation 1x - Select 4-lane operation
  [7] PCIE0_CTRL_MODE_SEL — Selects the operating mode 0 - Endpoint 1 - Root Complex
  [1:0] PCIE0_CTRL_GENERATION_SEL — Configures the PCIe generation support in the PCIe capabilities linked-list Field values (Others are reserved): 2'b01 - Gen2 - Controller advertises Gen1 & Gen2 capability and link operates at either speed 2'b10 - Gen3 - Controller advertises Gen1, Gen2, & Gen3 capability and link operates at any of the three speeds 2'b11 - Reserved
0x4074 CFG0_PCIE1_CTRL reset 0x2 — Controls PCIe1 operation
  [9:8] PCIE1_CTRL_LANE_COUNT — Configures the PCIe lane count 00 - Select 1-lane operation 01 - Select 2-lane operation 1x - Select 4-lane operation
  [7] PCIE1_CTRL_MODE_SEL — Selects the operating mode 0 - Endpoint 1 - Root Complex
  [1:0] PCIE1_CTRL_GENERATION_SEL — Configures the PCIe generation support in the PCIe capabilities linked-list Field values (Others are reserved): 2'b01 - Gen2 - Controller advertises Gen1 & Gen2 capability and link operates at either speed 2'b10 - Gen3 - Controller advertises Gen1, Gen2, & Gen3 capability and link operates at any of the three speeds 2'b11 - Reserved
0x4078 CFG0_PCIE2_CTRL reset 0x2 — Controls PCIe2 operation
  [9:8] PCIE2_CTRL_LANE_COUNT — Configures the PCIe lane count 00 - Select 1-lane operation 01 - Select 2-lane operation 1x - Select 4-lane operation (not supported)
  [7] PCIE2_CTRL_MODE_SEL — Selects the operating mode 0 - Endpoint 1 - Root Complex
  [1:0] PCIE2_CTRL_GENERATION_SEL — Configures the PCIe generation support in the PCIe capabilities linked-list Field values (Others are reserved): 2'b01 - Gen2 - Controller advertises Gen1 & Gen2 capability and link operates at either speed 2'b10 - Gen3 - Controller advertises Gen1, Gen2, & Gen3 capability and link operates at any of the three speeds 2'b11 - Reserved
0x407C CFG0_PCIE3_CTRL reset 0x2 — Controls PCIe3 operation
  [9:8] PCIE3_CTRL_LANE_COUNT — Configures the PCIe lane count 00 - Select 1-lane operation 01 - Select 2-lane operation 1x - Select 4-lane operation (not supported)
  [7] PCIE3_CTRL_MODE_SEL — Selects the operating mode 0 - Endpoint 1 - Root Complex
  [1:0] PCIE3_CTRL_GENERATION_SEL — Configures the PCIe generation support in the PCIe capabilities linked-list Field values (Others are reserved): 2'b01 - Gen2 - Controller advertises Gen1 & Gen2 capability and link operates at either speed 2'b10 - Gen3 - Controller advertises Gen1, Gen2, & Gen3 capability and link operates at any of the three speeds 2'b11 - Reserved
0x4080 CFG0_SERDES0_LN0_CTRL — Controls SERDES0 lane0 selection
  [1:0] SERDES0_LN0_CTRL_LANE_FUNC_SEL — Selects the SERDES0 lane0 function Field values (Others are reserved): 2'b00 - IP1 - Not Used 2'b01 - IP2 - PCIe1 Lane 0 2'b10 - IP3 - Not used 2'b11 - IP4 - Hyperlink (VUSR) Lane 0
0x4084 CFG0_SERDES0_LN1_CTRL — Controls SERDES0 lane1 selection
  [1:0] SERDES0_LN1_CTRL_LANE_FUNC_SEL — Selects the SERDES0 lane1 function Field values (Others are reserved): 2'b00 - IP1 - Not Used 2'b01 - IP2 - PCIe1 Lane 1 2'b10 - IP3 - Not Used 2'b11 - IP4 - Hyperlink (VUSR) Lane 1
0x4088 CFG0_SERDES0_LN2_CTRL — Controls SERDES0 lane2 selection
  [1:0] SERDES0_LN2_CTRL_LANE_FUNC_SEL — Selects the SERDES0 lane2 function Field values (Others are reserved): 2'b00 - IP1 - PCIe3 Lane 0 2'b01 - IP2 - PCIe1 Lane 2 2'b10 - IP3 - Not Used 2'b11 - Ip4 - Hyperlink (VUSR) Lane 2
0x408C CFG0_SERDES0_LN3_CTRL — Controls SERDES0 lane3 selection
  [1:0] SERDES0_LN3_CTRL_LANE_FUNC_SEL — Selects the SERDES0 lane3 function Field values (Others are reserved): 2'b00 - IP1 - PCIe3 Lane 1 2'b01 - IP2 - PCIe1 Lane 3 2'b10 - IP3 - USB3_0 2'b11 - IP4 - Hyperlink (VUSR) Lane 3
0x4090 CFG0_SERDES1_LN0_CTRL — Controls SERDES1 lane0 selection
  [1:0] SERDES1_LN0_CTRL_LANE_FUNC_SEL — Selects the SERDES1 lane0 function Field values (Others are reserved): 2'b00 - IP1 - Enet Switch Q/SGMII Lane 3 2'b01 - IP2 - PCIe0 Lane 0 2'b10 - IP3 - Not Used 2'b11 - IP4 - Not Used
0x4094 CFG0_SERDES1_LN1_CTRL — Controls SERDES1 lane1 selection
  [1:0] SERDES1_LN1_CTRL_LANE_FUNC_SEL — Selects the SERDES1 lane1 function Field values (Others are reserved): 2'b00 - IP1 - Enet Switch Q/SGMII Lane 4 2'b01 - IP2 - PCIe0 Lane 1 2'b10 - IP3 - Not Used 2'b11 - IP4 - Not Used
0x4098 CFG0_SERDES1_LN2_CTRL — Controls SERDES1 lane2 selection
  [1:0] SERDES1_LN2_CTRL_LANE_FUNC_SEL — Selects the SERDES1 lane2 function Field values (Others are reserved): 2'b00 - IP1 - Enet Switch Q/SGMII Lane 1 2'b01 - IP2 - PCIe0 Lane 2 2'b10 - IP3 - PCIe2 Lane 0 2'b11 - IP4 - Not Used
0x409C CFG0_SERDES1_LN3_CTRL — Controls SERDES1 lane3 selection
  [1:0] SERDES1_LN3_CTRL_LANE_FUNC_SEL — Selects the SERDES1 lane3 function Field values (Others are reserved): 2'b00 - IP1 - Enet Switch Q/SGMII Lane 2 2'b01 - IP2 - PCIe0 Lane 3 2'b10 - IP3 - PCIe2 Lane 1 2'b11 - IP4 - Not Used
0x40A0 CFG0_SERDES2_LN0_CTRL — Controls SERDES2 lane0 selection
  [1:0] SERDES2_LN0_CTRL_LANE_FUNC_SEL — Selects the SERDES2 lane0 function Field values (Others are reserved): 2'b00 - IP1 - Enet Switch Q/SGMII Lane 5 2'b01 - IP2 - Not Used 2'b10 - IP3 - Not Used 2'b11 - IP4 - Not Used
0x40A4 CFG0_SERDES2_LN1_CTRL — Controls SERDES2 lane1 selection
  [1:0] SERDES2_LN1_CTRL_LANE_FUNC_SEL — Selects the SERDES2 lane1 function Field values (Others are reserved): 2'b00 - IP1 - Enet Switch Q/SGMII Lane 6 2'b01 - IP2 - Not Used 2'b10 - IP3 - Not Used 2'b11 - IP4 - Not Used
0x40A8 CFG0_SERDES2_LN2_CTRL — Controls SERDES2 lane2 selection
  [1:0] SERDES2_LN2_CTRL_LANE_FUNC_SEL — Selects the SERDES2 lane2 functionProgramming this value to 2'b01 also selects SerDes2 to drive the CPSW Lane 0 PIPE interface input clock, data, and control signals. Field values (Others are reserved): 2'b00 - IP1 - Enet Switch Q/SGMII Lane 7 2'b01 - IP2 - Enet Switch Q/SGMII Lane 1 2'b10 - IP3 - Not Used 2'b11 - IP4 - Not Used
0x40AC CFG0_SERDES2_LN3_CTRL — Controls SERDES2 lane3 selection
  [1:0] SERDES2_LN3_CTRL_LANE_FUNC_SEL — Selects the SERDES2 lane3 functionProgramming this value to 2'b01 also selects SerDes2 to drive the CPSW Lane 1 PIPE interface input clock, data, and control signals. Field values (Others are reserved): 2'b00 - IP1 - Enet Switch Q/SGMII Lane 8 2'b01 - IP2 - Enet Switch Q/SGMII Lane 2 2'b10 - IP3 - Not Used 2'b11 - IP4 - Not Used
{0x40C0+4i} CFG0_SERDES4_LN{i}_CTRL (i=0..2) — Controls SERDES4 lane{i} selection
  [1:0] SERDES4_LN{i}_CTRL_LANE_FUNC_SEL — Selects the SERDES4 lane{i} functionProgramming this value to 2'b01 also selects SerDes4 to drive the CPSW Lane {i+5} PIPE interface input clock, data and control signals. Field values (Others are reserved): 2'b00 - IP1 - eDP Lane {i} 2'b01 - IP2 - Enet Switch Q/SGMII Lane {i+5} 2'b10 - IP3 - Not Used 2'b11 - IP4 - Hyperlink (VUSR) Lane {i}
0x40CC CFG0_SERDES4_LN3_CTRL — Controls SERDES4 lane3 selection
  [1:0] SERDES4_LN3_CTRL_LANE_FUNC_SEL — Selects the SERDES4 lane3 functionProgramming this value to 2'b01 also selects SerDes4 to drive the CPSW Lane 8 PIPE interface input clock, data and control signals. Field values (Others are reserved): 2'b00 - IP1 - eDP Lane 3 2'b01 - IP2 - Enet Switch Q/SGMII Lane 8 2'b10 - IP3 - USB3_0 2'b11 - IP4 - Hyperlink (VUSR) Lane 3
{0x40E0+4i} CFG0_SERDES{i}_CTRL (i=0..2) — Controls SERDES{i} operation
  [8] SERDES{i}_CTRL_RET_EN — Retention enable
0x40F0 CFG0_SERDES4_CTRL — Controls SERDES4 operation
  [8] SERDES4_CTRL_RET_EN — Retention enable
{0x4140+4i} CFG0_EPWM{i}_CTRL (i=0..2) — Controls ePWM{i} Operation
  [4] EPWM{i}_CTRL_EALLOW — Enable write access to ePWM tripzone and HRPWM config registers 0 - Disabled 1 - Enabled
  [0] EPWM{i}_CTRL_TB_CLKEN — Enable ePWM timebase clock 0 - Disabled 1 - EnabledThis bit is OR'd with SUP_CTRL7_pwm{i}_tb_clken. Setting the tb_clken in either register will start the timebase counter.
0x414C CFG0_EPWM3_CTRL — Controls ePWM3 Operation
  [10:8] EPWM3_CTRL_SYNCIN_SEL — Selects the source of the PWM3 synchronization input Field values (Others are reserved): 3'b000 - PWM3_SYNCIN Pin 3'b001 - PWM2 syncout signal, daisy chained 3'b010 - None 3'b011 - None 3'b100 - None 3'b101 - None 3'b110 - None 3'b111 - None
  [4] EPWM3_CTRL_EALLOW — Enable write access to ePWM tripzone and HRPWM config registers 0 - Disabled 1 - Enabled
  [0] EPWM3_CTRL_TB_CLKEN — Enable ePWM timebase clock 0 - Disabled 1 - EnabledThis bit is OR'd with SUP_CTRL7_pwm3_tb_clken. Setting the tb_clken in either register will start the timebase counter.
0x4150 CFG0_EPWM4_CTRL — Controls ePWM4 Operation
  [4] EPWM4_CTRL_EALLOW — Enable write access to ePWM tripzone and HRPWM config registers 0 - Disabled 1 - Enabled
  [0] EPWM4_CTRL_TB_CLKEN — Enable ePWM timebase clock 0 - Disabled 1 - EnabledThis bit is OR'd with SUP_CTRL7_pwm4_tb_clken. Setting the tb_clken in either register will start the timebase counter.
0x4154 CFG0_EPWM5_CTRL — Controls ePWM5 Operation
  [4] EPWM5_CTRL_EALLOW — Enable write access to ePWM tripzone and HRPWM config registers 0 - Disabled 1 - Enabled
  [0] EPWM5_CTRL_TB_CLKEN — Enable ePWM timebase clock 0 - Disabled 1 - EnabledThis bit is OR'd with SUP_CTRL7_pwm5_tb_clken. Setting the tb_clken in either register will start the timebase counter.
0x4160 CFG0_SOCA_SEL — Selects Start of Conversion A output signal source. Each ePWM provides a SOCA event that can be used to trigger external ADCs. All ePWM SOCA events are ORed together allowing any of the 6 ePWMs to generate the event (if enabled within the ePWM). This event is then muxed with an ICSSx host interrupt allowing either an ICSSx or ePWMs to source the SOCA event pin.
  [1:0] SOCA_SEL_SOCA_SEL — Selects the SOC A output source Field values (Others are reserved): 2'b00 - OR of all eHRPWM SOCA outputs 2'b01 - None 2'b10 - None 2'b11 - None
0x4164 CFG0_SOCB_SEL — Selects Start of Conversion B output signal source.. Each ePWM provides a SOCB event that can be used to trigger external ADCs. All ePWM SOCB events are ORed together allowing any of the 6 ePWMs to generate the event (if enabled within the ePWM).
  [1:0] SOCB_SEL_SOCB_SEL — Selects the SOC B output source Field values (Others are reserved): 2'b00 - OR of all eHRPWM SOCB ouputs 2'b01 - None 2'b10 - None 2'b11 - None
0x41A0 CFG0_EQEP_STAT ro — Displays status of EQEP modules
  [2] EQEP_STAT_PHASE_ERR2 — eQEP2 Phase error status 0 - No error 1 - Phase error occurred
  [1] EQEP_STAT_PHASE_ERR1 — eQEP1 Phase error status 0 - No error 1 - Phase error occurred
  [0] EQEP_STAT_PHASE_ERR0 — eQEP0 Phase error status 0 - No error 1 - Phase error occurred
0x41B4 CFG0_SDIO1_CTRL — Controls drive strength of MMC1 SDIO mode pins
  [4:0] SDIO1_CTRL_DRV_STR — Selects the SDIO drive strength
0x4200 CFG0_TIMER0_CTRL — Controls TIMER0 operation
  [2:0] TIMER0_CTRL_CAP_SEL — Selects the TIMERIO input pin for capture input signal. This control is only used when TIMER0 is configured for capture operation. Field values (Others are reserved): 3'b000 - Use TIMERIO0 pin 3'b001 - Use TIMERIO1 pin 3'b010 - Use TIMERIO2 pin 3'b011 - Use TIMERIO3 pin 3'b100 - Use TIMERIO4 pin 3'b101 - Use TIMERIO5 pin 3'b110 - Use TIMERIO6 pin 3'b111 - Use TIMERIO7 pin
